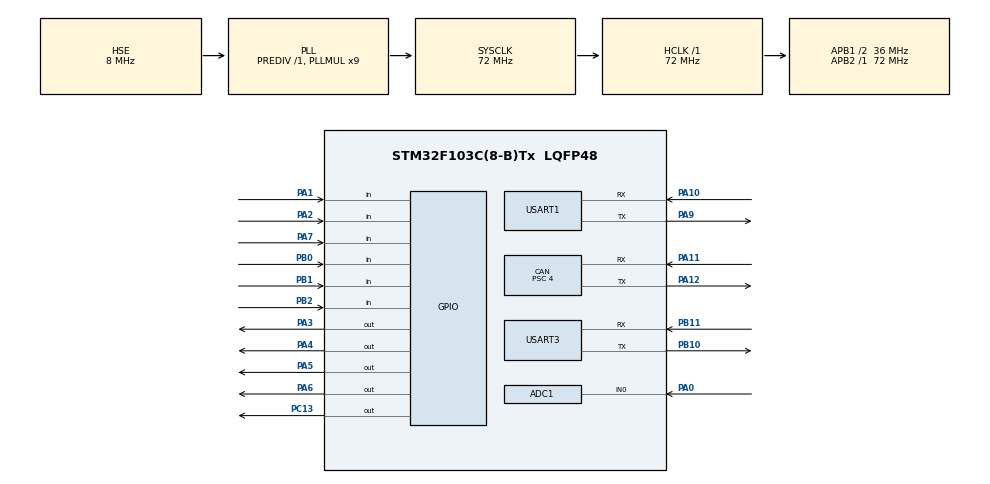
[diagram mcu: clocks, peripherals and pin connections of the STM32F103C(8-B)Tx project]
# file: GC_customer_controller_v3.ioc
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ADC1.Channel-3\#ChannelRegularConversion=ADC_CHANNEL_0
ADC1.NbrOfConversion=1
ADC1.NbrOfConversionFlag=1
ADC1.Rank-3\#ChannelRegularConversion=1
ADC1.SamplingTime-3\#ChannelRegularConversion=ADC_SAMPLETIME_239CYCLES_5
ADC1.master=1
CAN.BS1=CAN_BS1_4TQ
CAN.BS2=CAN_BS2_4TQ
CAN.CalculateBaudRate=1000000
CAN.CalculateTimeBit=1000
CAN.CalculateTimeQuantum=111.11111111111111
CAN.Prescaler=4
Dma.ADC1.0.Direction=DMA_PERIPH_TO_MEMORY
Dma.ADC1.0.Instance=DMA1_Channel1
Dma.ADC1.0.MemDataAlignment=DMA_MDATAALIGN_HALFWORD
Dma.ADC1.0.MemInc=DMA_MINC_ENABLE
Dma.ADC1.0.Mode=DMA_NORMAL
Dma.ADC1.0.PeriphDataAlignment=DMA_PDATAALIGN_HALFWORD
Dma.ADC1.0.PeriphInc=DMA_PINC_DISABLE
Dma.ADC1.0.Priority=DMA_PRIORITY_LOW
Dma.Request0=ADC1
FREERTOS.Tasks01=defaultTask,0,128,StartDefaultTask,Default,NULL,Dynamic,NULL,NULL
FREERTOS.configTOTAL_HEAP_SIZE=3072
Mcu.Family=STM32F1
Mcu.Name=STM32F103C(8-B)Tx
Mcu.Package=LQFP48
NVIC.CAN1_RX1_IRQn=true\:5\:0\:false\:false\:true\:true\:true\:true\:true
NVIC.CAN1_SCE_IRQn=true\:5\:0\:false\:false\:true\:true\:true\:true\:true
NVIC.DMA1_Channel1_IRQn=true\:5\:0\:false\:false\:true\:true\:false\:true\:true
NVIC.PriorityGroup=NVIC_PRIORITYGROUP_4
NVIC.TIM1_UP_IRQn=true\:15\:0\:false\:false\:true\:false\:false\:true\:true
NVIC.TimeBase=TIM1_UP_IRQn
NVIC.TimeBaseIP=TIM1
NVIC.USB_HP_CAN1_TX_IRQn=true\:5\:0\:false\:false\:true\:true\:true\:true\:true
NVIC.USB_LP_CAN1_RX0_IRQn=true\:5\:0\:false\:false\:true\:true\:true\:true\:true
PA0-WKUP.Signal=ADCx_IN0
PA1.Signal=GPIO_Input
PA10.Mode=Asynchronous
PA10.Signal=USART1_RX
PA11.Mode=CAN_Activate
PA11.Signal=CAN_RX
PA12.Mode=CAN_Activate
PA12.Signal=CAN_TX
PA13.Mode=Serial_Wire
PA13.Signal=SYS_JTMS-SWDIO
PA14.Mode=Serial_Wire
PA14.Signal=SYS_JTCK-SWCLK
PA2.Signal=GPIO_Input
PA3.Signal=GPIO_Output
PA4.Signal=GPIO_Output
PA5.Signal=GPIO_Output
PA6.Signal=GPIO_Output
PA7.Signal=GPIO_Input
PA9.Mode=Asynchronous
PA9.Signal=USART1_TX
PB0.Signal=GPIO_Input
PB1.Signal=GPIO_Input
PB10.Mode=Asynchronous
PB10.Signal=USART3_TX
PB11.Mode=Asynchronous
PB11.Signal=USART3_RX
PB2.Signal=GPIO_Input
PC13-TAMPER-RTC.Signal=GPIO_Output
PD0-OSC_IN.Mode=HSE-External-Oscillator
PD0-OSC_IN.Signal=RCC_OSC_IN
PD1-OSC_OUT.Mode=HSE-External-Oscillator
PD1-OSC_OUT.Signal=RCC_OSC_OUT
ProjectManager.HeapSize=0x200
ProjectManager.StackSize=0x400
ProjectManager.TargetToolchain=MDK-ARM V5.32
RCC.ADCPresc=RCC_ADCPCLK2_DIV6
RCC.AHBFreq_Value=72000000
RCC.APB1CLKDivider=RCC_HCLK_DIV2
RCC.APB1Freq_Value=36000000
RCC.APB1TimFreq_Value=72000000
RCC.APB2Freq_Value=72000000
RCC.APB2TimFreq_Value=72000000
RCC.HCLKFreq_Value=72000000
RCC.PLLMUL=RCC_PLL_MUL9
RCC.PLLSourceVirtual=RCC_PLLSOURCE_HSE
RCC.SYSCLKFreq_VALUE=72000000
RCC.SYSCLKSource=RCC_SYSCLKSOURCE_PLLCLK
RCC.USBFreq_Value=72000000
SH.ADCx_IN0.0=ADC1_IN0,IN0
USART1.VirtualMode=VM_ASYNC
USART3.VirtualMode=VM_ASYNC
VP_CRC_VS_CRC.Mode=CRC_Activate
VP_FREERTOS_VS_CMSIS_V1.Mode=CMSIS_V1
VP_SYS_VS_tim1.Mode=TIM1
board=custom

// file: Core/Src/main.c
/* USER CODE BEGIN Header */
/**
  ******************************************************************************
  * @file           : main.c
  * @brief          : Main program body
  ******************************************************************************
  * @attention
  *
  * Copyright (c) 2024 STMicroelectronics.
  * All rights reserved.
  *
  * This software is licensed under terms that can be found in the LICENSE file
  * in the root directory of this software component.
  * If no LICENSE file comes with this software, it is provided AS-IS.
  *
  ******************************************************************************
  */
/* USER CODE END Header */
#include "main.h"
#include "cmsis_os.h"
#include "adc.h"
#include "can.h"
#include "crc.h"
#include "dma.h"
#include "usart.h"
#include "gpio.h"

void SystemClock_Config(void);
void MX_FREERTOS_Init(void);

int main(void)
{

  /* MCU Configuration--------------------------------------------------------*/

  /* Reset of all peripherals, Initializes the Flash interface and the Systick. */
  HAL_Init();

  /* Configure the system clock */
  SystemClock_Config();

  /* Initialize all configured peripherals */
  MX_GPIO_Init();
  MX_DMA_Init();
  MX_ADC1_Init();
  MX_CAN_Init();
  MX_CRC_Init();
  MX_USART1_UART_Init();
  MX_USART3_UART_Init();

  /* Call init function for freertos objects (in freertos.c) */
  MX_FREERTOS_Init();

  /* Start scheduler */
  osKernelStart();

  /* We should never get here as control is now taken by the scheduler */
  /* Infinite loop */
  while (1)
  {

  }
}

void SystemClock_Config(void)
{
  RCC_OscInitTypeDef RCC_OscInitStruct = {0};
  RCC_ClkInitTypeDef RCC_ClkInitStruct = {0};
  RCC_PeriphCLKInitTypeDef PeriphClkInit = {0};

  /** Initializes the RCC Oscillators according to the specified parameters
  * in the RCC_OscInitTypeDef structure.
  */
  RCC_OscInitStruct.OscillatorType = RCC_OSCILLATORTYPE_HSE;
  RCC_OscInitStruct.HSEState = RCC_HSE_ON;
  RCC_OscInitStruct.HSEPredivValue = RCC_HSE_PREDIV_DIV1;
  RCC_OscInitStruct.HSIState = RCC_HSI_ON;
  RCC_OscInitStruct.PLL.PLLState = RCC_PLL_ON;
  RCC_OscInitStruct.PLL.PLLSource = RCC_PLLSOURCE_HSE;
  RCC_OscInitStruct.PLL.PLLMUL = RCC_PLL_MUL9;
  if (HAL_RCC_OscConfig(&RCC_OscInitStruct) != HAL_OK)
  {
    Error_Handler();
  }

  /** Initializes the CPU, AHB and APB buses clocks
  */
  RCC_ClkInitStruct.ClockType = RCC_CLOCKTYPE_HCLK|RCC_CLOCKTYPE_SYSCLK
                              |RCC_CLOCKTYPE_PCLK1|RCC_CLOCKTYPE_PCLK2;
  RCC_ClkInitStruct.SYSCLKSource = RCC_SYSCLKSOURCE_PLLCLK;
  RCC_ClkInitStruct.AHBCLKDivider = RCC_SYSCLK_DIV1;
  RCC_ClkInitStruct.APB1CLKDivider = RCC_HCLK_DIV2;
  RCC_ClkInitStruct.APB2CLKDivider = RCC_HCLK_DIV1;

  if (HAL_RCC_ClockConfig(&RCC_ClkInitStruct, FLASH_LATENCY_2) != HAL_OK)
  {
    Error_Handler();
  }
  PeriphClkInit.PeriphClockSelection = RCC_PERIPHCLK_ADC;
  PeriphClkInit.AdcClockSelection = RCC_ADCPCLK2_DIV6;
  if (HAL_RCCEx_PeriphCLKConfig(&PeriphClkInit) != HAL_OK)
  {
    Error_Handler();
  }
}

void HAL_TIM_PeriodElapsedCallback(TIM_HandleTypeDef *htim)
{
  if (htim->Instance == TIM1) {
    HAL_IncTick();
  }
}

void Error_Handler(void)
{
  __disable_irq();
  while (1)
  {
  }
}

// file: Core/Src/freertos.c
/* USER CODE BEGIN Header */
/**
  ******************************************************************************
  * File Name          : freertos.c
  * Description        : Code for freertos applications
  ******************************************************************************
  * @attention
  *
  * Copyright (c) 2024 STMicroelectronics.
  * All rights reserved.
  *
  * This software is licensed under terms that can be found in the LICENSE file
  * in the root directory of this software component.
  * If no LICENSE file comes with this software, it is provided AS-IS.
  *
  ******************************************************************************
  */
/* USER CODE END Header */

#include "FreeRTOS.h"
#include "task.h"
#include "main.h"
#include "cmsis_os.h"

/* USER CODE BEGIN Variables */
osThreadId joint_task_handle;
osThreadId message_task_handle;
osThreadId message_task_img_tran_handle;
/* USER CODE END Variables */
osThreadId defaultTaskHandle;

/* USER CODE BEGIN FunctionPrototypes */
void joint_task(void const * argument);
void message_task(void const * argument);
void StartSendDataTask(void const *argument);
/* USER CODE END FunctionPrototypes */

void StartDefaultTask(void const * argument);

void MX_FREERTOS_Init(void); /* (MISRA C 2004 rule 8.1) */

/* GetIdleTaskMemory prototype (linked to static allocation support) */
void vApplicationGetIdleTaskMemory( StaticTask_t **ppxIdleTaskTCBBuffer, StackType_t **ppxIdleTaskStackBuffer, uint32_t *pulIdleTaskStackSize );

/* USER CODE BEGIN GET_IDLE_TASK_MEMORY */
static StaticTask_t xIdleTaskTCBBuffer;
static StackType_t xIdleStack[configMINIMAL_STACK_SIZE];

void vApplicationGetIdleTaskMemory( StaticTask_t **ppxIdleTaskTCBBuffer, StackType_t **ppxIdleTaskStackBuffer, uint32_t *pulIdleTaskStackSize )
{
  *ppxIdleTaskTCBBuffer = &xIdleTaskTCBBuffer;
  *ppxIdleTaskStackBuffer = &xIdleStack[0];
  *pulIdleTaskStackSize = configMINIMAL_STACK_SIZE;
  /* place for user code */
}
/* USER CODE END GET_IDLE_TASK_MEMORY */

void MX_FREERTOS_Init(void) {

  /* Create the thread(s) */
  /* definition and creation of defaultTask */
  osThreadDef(defaultTask, StartDefaultTask, osPriorityNormal, 0, 128);
  defaultTaskHandle = osThreadCreate(osThread(defaultTask), NULL);

  /* USER CODE BEGIN RTOS_THREADS */
  /* add threads, ... */
  osThreadDef(messageTask_img_tran, StartSendDataTask, osPriorityHigh, 0, 256);
  message_task_img_tran_handle = osThreadCreate(osThread(messageTask_img_tran), NULL);
  osThreadDef(jointTask, joint_task, osPriorityHigh, 0, 256);
  joint_task_handle = osThreadCreate(osThread(jointTask), NULL);
  osThreadDef(messageTask, message_task, osPriorityHigh, 0, 128);
  message_task_handle = osThreadCreate(osThread(messageTask), NULL);

  /* USER CODE END RTOS_THREADS */

}

void StartDefaultTask(void const * argument)
{
  /* USER CODE BEGIN StartDefaultTask */
  /* Infinite loop */
  for(;;)
  {
    osDelay(10000);
  }
  /* USER CODE END StartDefaultTask */
}
